VERSION ""

NS_ :

BS_:

BU_:

BO_ 3221225472 VECTOR__INDEPENDENT_SIG_MSG: 0 Vector__XXX
 SG_ stop_b : 0|12@0- (0.01,0) [-20.48|20.47] "" Vector__XXX
 SG_ stop_flag : 0|1@0+ (1,0) [0|1] "" Vector__XXX
 SG_ pole_type : 0|2@0+ (1,0) [0|3] "" Vector__XXX
 SG_ pole12_HA : 0|12@0- (0.05,0) [-102.4|102.35] "deg" Vector__XXX

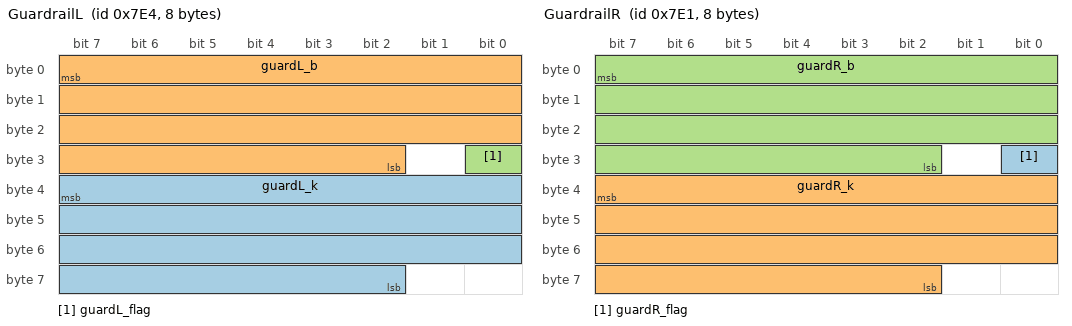
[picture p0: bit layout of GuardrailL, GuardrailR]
BO_ 2020 GuardrailL: 8 Vector__XXX
 SG_ guardL_k : 39|30@0- (0.001,0) [-536870.912|536870.911] "" Vector__XXX
 SG_ guardL_b : 7|30@0- (0.001,0) [-536870.912|536870.911] "" Vector__XXX
 SG_ guardL_flag : 24|1@0+ (1,0) [0|1] "" Vector__XXX

BO_ 2017 GuardrailR: 8 Vector__XXX
 SG_ guardR_flag : 24|1@0+ (1,0) [0|1] "" Vector__XXX
 SG_ guardR_k : 39|30@0- (0.001,0) [-536870.912|536870.911] "" Vector__XXX
 SG_ guardR_b : 7|30@0- (0.001,0) [-536870.912|536870.911] "" Vector__XXX

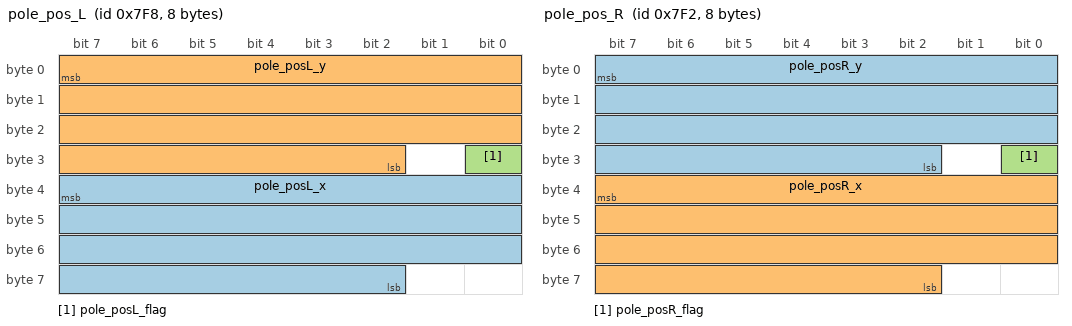
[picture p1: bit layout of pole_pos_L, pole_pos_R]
BO_ 2040 pole_pos_L: 8 Vector__XXX
 SG_ pole_posL_x : 39|30@0- (0.001,0) [-536870.912|536870.911] "" Vector__XXX
 SG_ pole_posL_y : 7|30@0- (0.001,0) [-536870.912|536870.911] "" Vector__XXX
 SG_ pole_posL_flag : 24|1@0+ (1,0) [0|1] "" Vector__XXX

BO_ 2034 pole_pos_R: 8 Vector__XXX
 SG_ pole_posR_y : 7|30@0- (0.001,0) [-536870.912|536870.911] "" Vector__XXX
 SG_ pole_posR_x : 39|30@0- (0.001,0) [-536870.912|536870.911] "" Vector__XXX
 SG_ pole_posR_flag : 24|1@0+ (1,0) [0|1] "" Vector__XXX

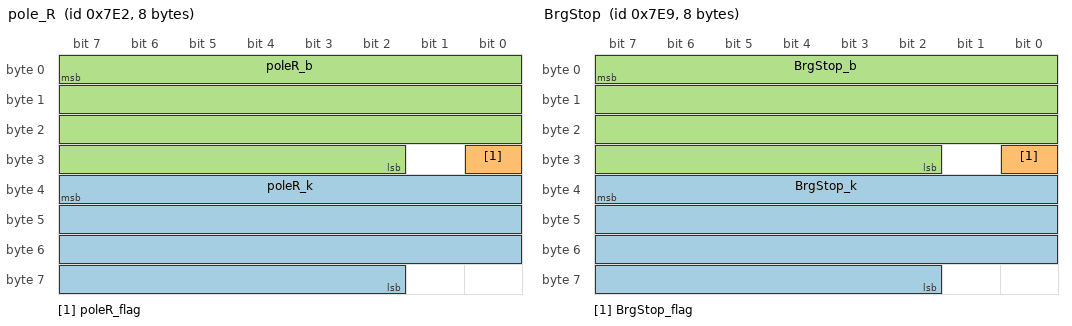
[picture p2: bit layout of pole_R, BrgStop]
BO_ 2018 pole_R: 8 Vector__XXX
 SG_ poleR_k : 39|30@0- (0.001,0) [-536870.912|536870.911] "" Vector__XXX
 SG_ poleR_flag : 24|1@0+ (1,0) [0|1] "" Vector__XXX
 SG_ poleR_b : 7|30@0- (0.001,0) [-536870.912|536870.911] "" Vector__XXX

BO_ 2025 BrgStop: 8 Vector__XXX
 SG_ BrgStop_k : 39|30@0- (0.001,0) [-536870.912|536870.911] "" Vector__XXX
 SG_ BrgStop_flag : 24|1@0+ (1,0) [0|1] "" Vector__XXX
 SG_ BrgStop_b : 7|30@0- (0.001,0) [-536870.912|536870.911] "" Vector__XXX

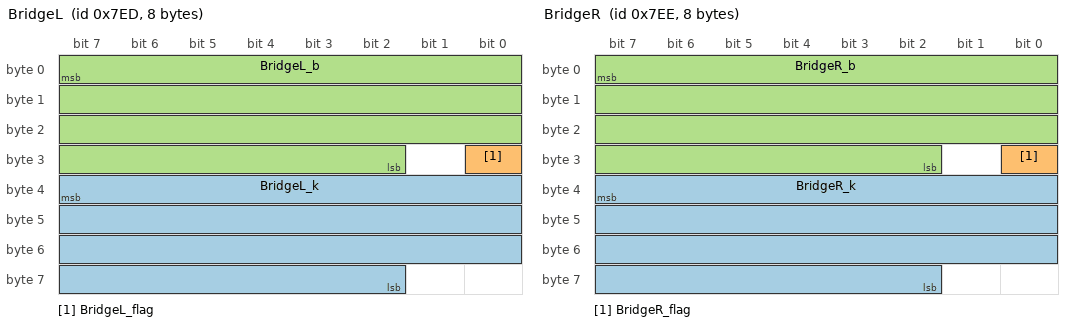
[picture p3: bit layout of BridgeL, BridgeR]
BO_ 2029 BridgeL: 8 Vector__XXX
 SG_ BridgeL_k : 39|30@0- (0.001,0) [-536870.912|536870.911] "" Vector__XXX
 SG_ BridgeL_flag : 24|1@0+ (1,0) [0|1] "" Vector__XXX
 SG_ BridgeL_b : 7|30@0- (0.001,0) [-536870.912|536870.911] "" Vector__XXX

BO_ 2030 BridgeR: 8 Vector__XXX
 SG_ BridgeR_k : 39|30@0- (0.001,0) [-536870.912|536870.911] "" Vector__XXX
 SG_ BridgeR_flag : 24|1@0+ (1,0) [0|1] "" Vector__XXX
 SG_ BridgeR_b : 7|30@0- (0.001,0) [-536870.912|536870.911] "" Vector__XXX

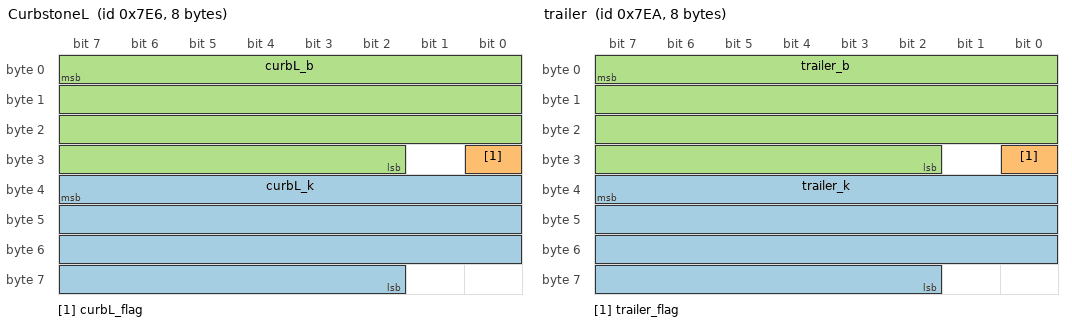
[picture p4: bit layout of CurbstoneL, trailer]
BO_ 2022 CurbstoneL: 8 Vector__XXX
 SG_ curbL_k : 39|30@0- (0.001,0) [-536870.912|536870.911] "" Vector__XXX
 SG_ curbL_flag : 24|1@0+ (1,0) [0|1] "" Vector__XXX
 SG_ curbL_b : 7|30@0- (0.001,0) [-536870.912|536870.911] "" Vector__XXX

BO_ 2026 trailer: 8 Vector__XXX
 SG_ trailer_k : 39|30@0- (0.001,0) [-536870.912|536870.911] "" Vector__XXX
 SG_ trailer_flag : 24|1@0+ (1,0) [0|1] "" Vector__XXX
 SG_ trailer_b : 7|30@0- (0.001,0) [-536870.912|536870.911] "" Vector__XXX

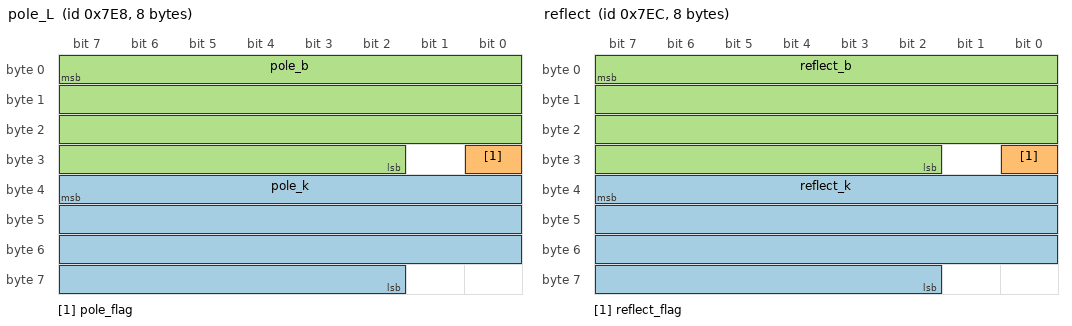
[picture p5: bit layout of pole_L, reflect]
BO_ 2024 pole_L: 8 Vector__XXX
 SG_ pole_k : 39|30@0- (0.001,0) [-536870.912|536870.911] "" Vector__XXX
 SG_ pole_flag : 24|1@0+ (1,0) [0|1] "" Vector__XXX
 SG_ pole_b : 7|30@0- (0.001,0) [-536870.912|536870.911] "" Vector__XXX

BO_ 2028 reflect: 8 Vector__XXX
 SG_ reflect_k : 39|30@0- (0.001,0) [-536870.912|536870.911] "" Vector__XXX
 SG_ reflect_flag : 24|1@0+ (1,0) [0|1] "" Vector__XXX
 SG_ reflect_b : 7|30@0- (0.001,0) [-536870.912|536870.911] "" Vector__XXX

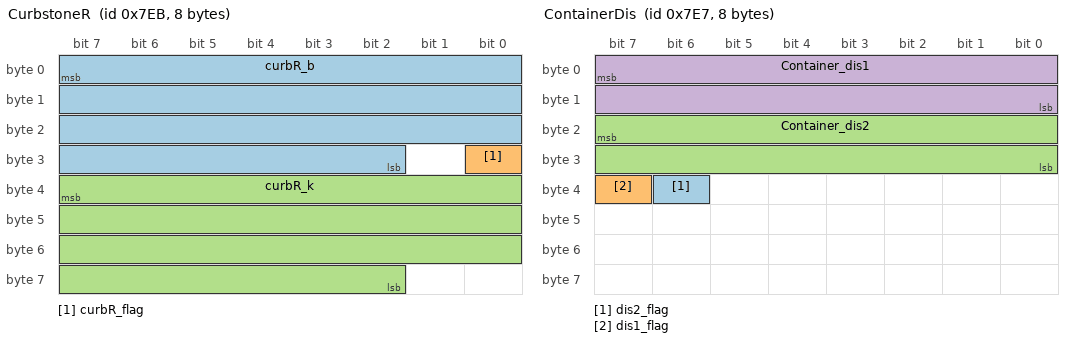
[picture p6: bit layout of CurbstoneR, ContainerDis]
BO_ 2027 CurbstoneR: 8 Vector__XXX
 SG_ curbR_b : 7|30@0- (0.001,0) [-536870.912|536870.911] "" Vector__XXX
 SG_ curbR_flag : 24|1@0+ (1,0) [0|1] "" Vector__XXX
 SG_ curbR_k : 39|30@0- (0.001,0) [-536870.912|536870.911] "" Vector__XXX

BO_ 2023 ContainerDis: 8 Vector__XXX
 SG_ dis2_flag : 38|1@0+ (1,0) [0|1] "" Vector__XXX
 SG_ dis1_flag : 39|1@0+ (1,0) [0|1] "" Vector__XXX
 SG_ Container_dis2 : 23|16@0- (0.001,0) [-32.768|32.767] "" Vector__XXX
 SG_ Container_dis1 : 7|16@0- (0.001,0) [-32.768|32.767] "" Vector__XXX

CM_ BO_ 3221225472 "This is a message for not used signals, created by Vector CANdb++ DBC OLE DB Provider.";
BA_DEF_  "BusType" STRING ;
BA_DEF_  "DBName" STRING ;
BA_DEF_ SG_  "GenSigSendType" ENUM  "cycle","OnChange","OnWrite","IfActive","OnChangeWithRepetition","OnWriteWithRepetition","IfActiveWithRepetition";
BA_DEF_ BO_  "GenMsgSendType" ENUM  "cycle","NoSendType","IfActive";
BA_DEF_ BU_  "NmNode" ENUM  "Not","Yes";
BA_DEF_ BU_  "NodeLayerModules" STRING ;
BA_DEF_DEF_  "BusType" "";
BA_DEF_DEF_  "DBName" "";
BA_DEF_DEF_  "GenSigSendType" "cycle";
BA_DEF_DEF_  "GenMsgSendType" "cycle";
BA_DEF_DEF_  "NmNode" "Not";
BA_DEF_DEF_  "NodeLayerModules" "CANoeILNLVector.dll";
BA_ "BusType" "CAN";
BA_ "DBName" "Lidar_other";
